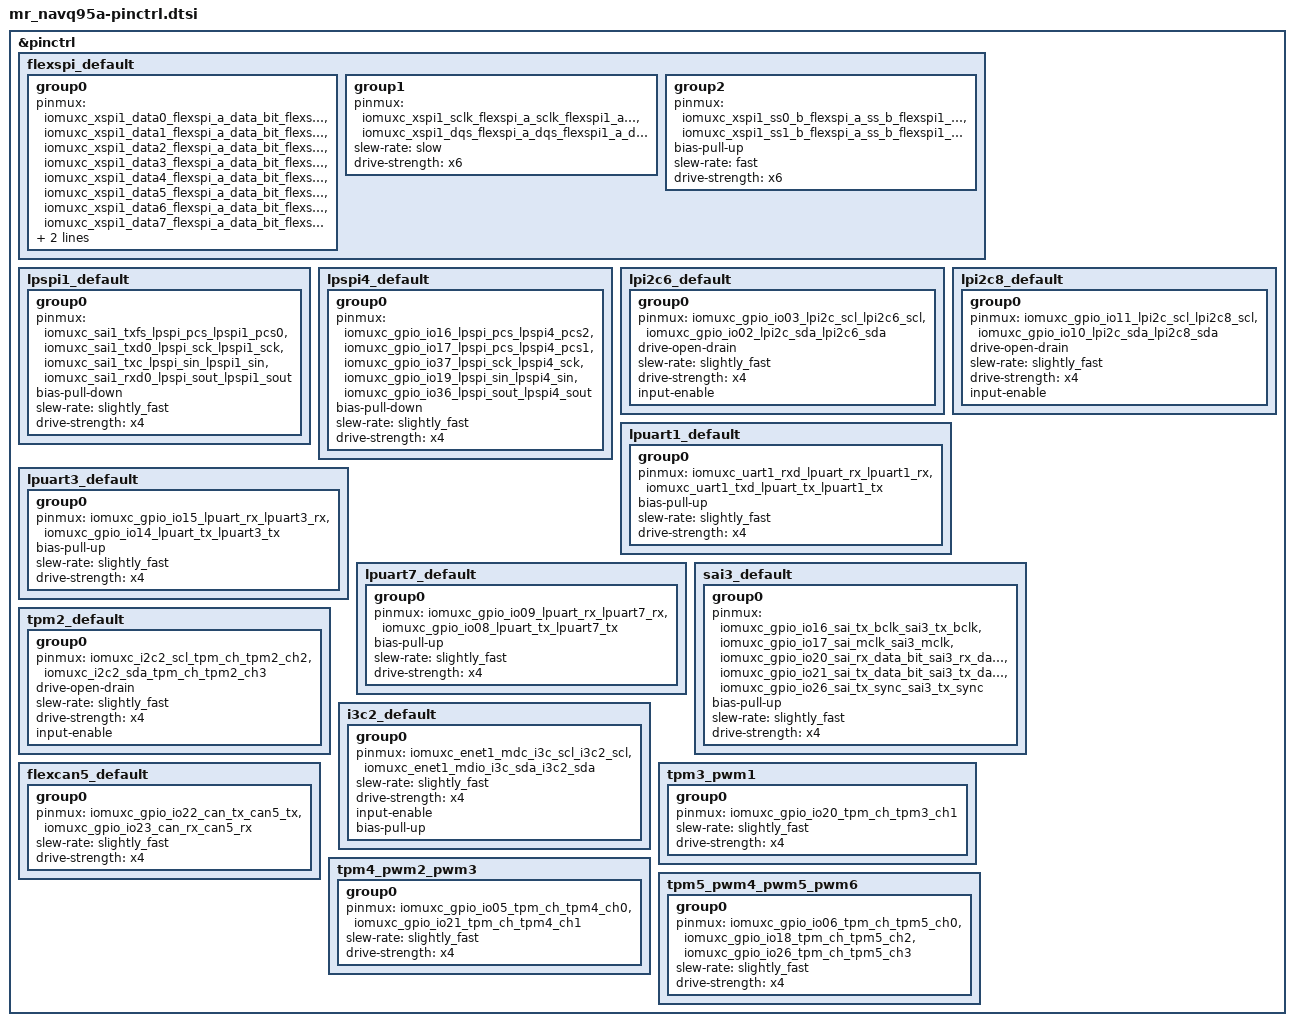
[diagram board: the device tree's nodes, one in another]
/*
 * Copyright 2025 NXP
 * SPDX-License-Identifier: Apache-2.0
 */

#include <nxp/nxp_imx/mimx9596avzxn-pinctrl.dtsi>

&pinctrl {
	flexspi_default: flexspi_default {
		group0 {
			pinmux = <&iomuxc_xspi1_data0_flexspi_a_data_bit_flexspi1_a_data_bit0>,
				<&iomuxc_xspi1_data1_flexspi_a_data_bit_flexspi1_a_data_bit1>,
				<&iomuxc_xspi1_data2_flexspi_a_data_bit_flexspi1_a_data_bit2>,
				<&iomuxc_xspi1_data3_flexspi_a_data_bit_flexspi1_a_data_bit3>,
				<&iomuxc_xspi1_data4_flexspi_a_data_bit_flexspi1_a_data_bit4>,
				<&iomuxc_xspi1_data5_flexspi_a_data_bit_flexspi1_a_data_bit5>,
				<&iomuxc_xspi1_data6_flexspi_a_data_bit_flexspi1_a_data_bit6>,
				<&iomuxc_xspi1_data7_flexspi_a_data_bit_flexspi1_a_data_bit7>;
			slew-rate = "slow";
			drive-strength = "x1";
		};
		group1 {
			pinmux = <&iomuxc_xspi1_sclk_flexspi_a_sclk_flexspi1_a_sclk>,
				<&iomuxc_xspi1_dqs_flexspi_a_dqs_flexspi1_a_dqs>;
			slew-rate = "slow";
			drive-strength = "x6";
		};
		group2 {
			pinmux = <&iomuxc_xspi1_ss0_b_flexspi_a_ss_b_flexspi1_a_ss0_b>,
				<&iomuxc_xspi1_ss1_b_flexspi_a_ss_b_flexspi1_a_ss1_b>;
			bias-pull-up;
			slew-rate = "fast";
			drive-strength = "x6";
		};
	};

	lpspi1_default: lpspi1_default {
		group0 {
			pinmux = <&iomuxc_sai1_txfs_lpspi_pcs_lpspi1_pcs0>,
				<&iomuxc_sai1_txd0_lpspi_sck_lpspi1_sck>,
				<&iomuxc_sai1_txc_lpspi_sin_lpspi1_sin>,
				<&iomuxc_sai1_rxd0_lpspi_sout_lpspi1_sout>;
			/*<&iomuxc_sai1_txfs_gpio_io_bit_gpio1_io_bit11>, GPIO CS*/
			bias-pull-down;
			slew-rate = "slightly_fast";
			drive-strength = "x4";
		};
	};

	lpspi4_default: lpspi4_default {
		group0 {
			pinmux = <&iomuxc_gpio_io16_lpspi_pcs_lpspi4_pcs2>,
			    <&iomuxc_gpio_io17_lpspi_pcs_lpspi4_pcs1>,
				<&iomuxc_gpio_io37_lpspi_sck_lpspi4_sck>,
				<&iomuxc_gpio_io19_lpspi_sin_lpspi4_sin>,
				<&iomuxc_gpio_io36_lpspi_sout_lpspi4_sout>;
			/* GPIO CS */
			/* <&iomuxc_gpio_io16_gpio_io_bit_gpio2_io_bit16>,
				<&iomuxc_gpio_io17_gpio_io_bit_gpio2_io_bit17>,*/
			bias-pull-down;
			slew-rate = "slightly_fast";
			drive-strength = "x4";
		};
	};

	lpi2c6_default: lpi2c6_default {
		group0 {
			pinmux = <&iomuxc_gpio_io03_lpi2c_scl_lpi2c6_scl>,
				<&iomuxc_gpio_io02_lpi2c_sda_lpi2c6_sda>;
			drive-open-drain;
			slew-rate = "slightly_fast";
			drive-strength = "x4";
			input-enable;
		};
	};

	lpi2c8_default: lpi2c8_default {
		group0 {
			pinmux = <&iomuxc_gpio_io11_lpi2c_scl_lpi2c8_scl>,
				<&iomuxc_gpio_io10_lpi2c_sda_lpi2c8_sda>;
			drive-open-drain;
			slew-rate = "slightly_fast";
			drive-strength = "x4";
			input-enable;
		};
	};

	lpuart1_default: lpuart1_default {
		group0 {
			pinmux = <&iomuxc_uart1_rxd_lpuart_rx_lpuart1_rx>,
				<&iomuxc_uart1_txd_lpuart_tx_lpuart1_tx>;
			bias-pull-up;
			slew-rate = "slightly_fast";
			drive-strength = "x4";
		};
	};

	lpuart3_default: lpuart3_default {
		group0 {
			pinmux = <&iomuxc_gpio_io15_lpuart_rx_lpuart3_rx>,
				<&iomuxc_gpio_io14_lpuart_tx_lpuart3_tx>;
			bias-pull-up;
			slew-rate = "slightly_fast";
			drive-strength = "x4";
		};
	};

	lpuart7_default: lpuart7_default {
		group0 {
			pinmux = <&iomuxc_gpio_io09_lpuart_rx_lpuart7_rx>,
				<&iomuxc_gpio_io08_lpuart_tx_lpuart7_tx>;
			bias-pull-up;
			slew-rate = "slightly_fast";
			drive-strength = "x4";
		};
	};

	sai3_default: sai3_default {
		group0 {
			pinmux = <&iomuxc_gpio_io16_sai_tx_bclk_sai3_tx_bclk>,
				 <&iomuxc_gpio_io17_sai_mclk_sai3_mclk>,
				 <&iomuxc_gpio_io20_sai_rx_data_bit_sai3_rx_data_bit0>,
				 <&iomuxc_gpio_io21_sai_tx_data_bit_sai3_tx_data_bit0>,
				 <&iomuxc_gpio_io26_sai_tx_sync_sai3_tx_sync>;
			bias-pull-up;
			slew-rate = "slightly_fast";
			drive-strength = "x4";
		};
	};

	tpm2_default: tpm2_default {
		group0 {
			pinmux = <&iomuxc_i2c2_scl_tpm_ch_tpm2_ch2>,
				<&iomuxc_i2c2_sda_tpm_ch_tpm2_ch3>;
			drive-open-drain;
			slew-rate = "slightly_fast";
			drive-strength = "x4";
			input-enable;
		};
	};

	i3c2_default: i3c2_default {
		group0 {
			pinmux = <&iomuxc_enet1_mdc_i3c_scl_i3c2_scl>,
				<&iomuxc_enet1_mdio_i3c_sda_i3c2_sda>;
			slew-rate = "slightly_fast";
			drive-strength = "x4";
			input-enable;
			bias-pull-up;
		};
	};

	flexcan5_default: flexcan5_default {
		group0 {
			pinmux = <&iomuxc_gpio_io22_can_tx_can5_tx>,
				<&iomuxc_gpio_io23_can_rx_can5_rx>;
			slew-rate = "slightly_fast";
			drive-strength = "x4";
		};
	};

	/* pwm pins */
	tpm3_pwm1: tpm3_pwm1 {
		group0 {
			pinmux = <&iomuxc_gpio_io20_tpm_ch_tpm3_ch1>;
			slew-rate = "slightly_fast";
			drive-strength = "x4";
		};
	};

	tpm4_pwm2_pwm3: tpm4_pwm2_pwm3 {
		group0 {
			pinmux = <&iomuxc_gpio_io05_tpm_ch_tpm4_ch0>,
				<&iomuxc_gpio_io21_tpm_ch_tpm4_ch1>;
			slew-rate = "slightly_fast";
			drive-strength = "x4";
		};
	};

	tpm5_pwm4_pwm5_pwm6: tpm5_pwm4_pwm5_pwm6 {
		group0 {
			pinmux = <&iomuxc_gpio_io06_tpm_ch_tpm5_ch0>,
				<&iomuxc_gpio_io18_tpm_ch_tpm5_ch2>,
				<&iomuxc_gpio_io26_tpm_ch_tpm5_ch3>;
			slew-rate = "slightly_fast";
			drive-strength = "x4";
		};
	};
};
